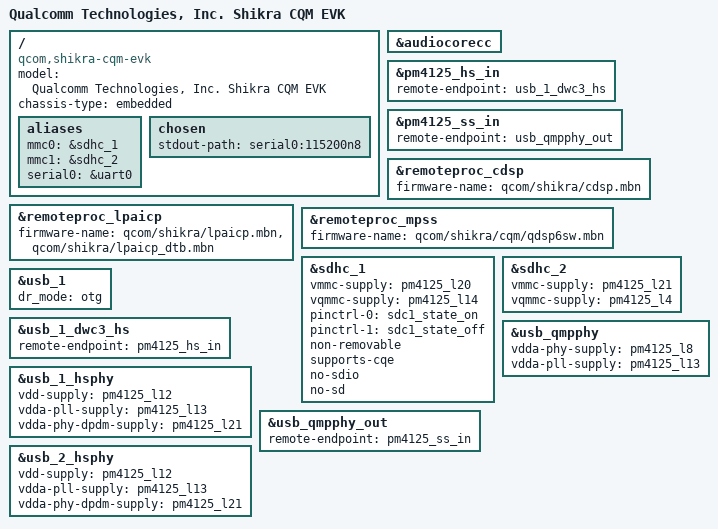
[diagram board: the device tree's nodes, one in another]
// SPDX-License-Identifier: BSD-3-Clause
/*
 * Copyright (c) Qualcomm Technologies, Inc. and/or its subsidiaries.
 */

/dts-v1/;

#include "shikra-cqm-som.dtsi"
#include "shikra-evk.dtsi"
#include <dt-bindings/gpio/gpio.h>

/ {
	model = "Qualcomm Technologies, Inc. Shikra CQM EVK";
	compatible = "qcom,shikra-cqm-evk", "qcom,shikra-cqm-som", "qcom,shikra";
	chassis-type = "embedded";

	aliases {
		mmc0 = &sdhc_1;
		mmc1 = &sdhc_2; /* SDC2 SD card slot */
		serial0 = &uart0;
	};

	chosen {
		stdout-path = "serial0:115200n8";
	};
};

&audiocorecc {
	status = "okay";
};

&pm4125_hs_in {
	remote-endpoint = <&usb_1_dwc3_hs>;
};

&pm4125_ss_in {
	remote-endpoint = <&usb_qmpphy_out>;
};

&remoteproc_cdsp {
	firmware-name = "qcom/shikra/cdsp.mbn";

	status = "okay";
};

&remoteproc_lpaicp {
	firmware-name = "qcom/shikra/lpaicp.mbn",
			"qcom/shikra/lpaicp_dtb.mbn";

	status = "okay";
};

&remoteproc_mpss {
	firmware-name = "qcom/shikra/cqm/qdsp6sw.mbn";

	status = "okay";
};

&sdhc_1 {
	vmmc-supply = <&pm4125_l20>;
	vqmmc-supply = <&pm4125_l14>;

	pinctrl-0 = <&sdc1_state_on>;
	pinctrl-1 = <&sdc1_state_off>;
	pinctrl-names = "default", "sleep";

	non-removable;
	supports-cqe;
	no-sdio;
	no-sd;

	status = "okay";
};

&sdhc_2 {
	vmmc-supply = <&pm4125_l21>;
	vqmmc-supply = <&pm4125_l4>;

	status = "okay";
};

&usb_1 {
	dr_mode = "otg";
};

&usb_1_dwc3_hs {
	remote-endpoint = <&pm4125_hs_in>;
};

&usb_1_hsphy {
	vdd-supply = <&pm4125_l12>;
	vdda-pll-supply = <&pm4125_l13>;
	vdda-phy-dpdm-supply = <&pm4125_l21>;

	status = "okay";
};

&usb_qmpphy {
	vdda-phy-supply = <&pm4125_l8>;
	vdda-pll-supply = <&pm4125_l13>;

	status = "okay";
};

&usb_qmpphy_out {
	remote-endpoint = <&pm4125_ss_in>;
};

&usb_2_hsphy {
	vdd-supply = <&pm4125_l12>;
	vdda-pll-supply = <&pm4125_l13>;
	vdda-phy-dpdm-supply = <&pm4125_l21>;

	status = "okay";
};
